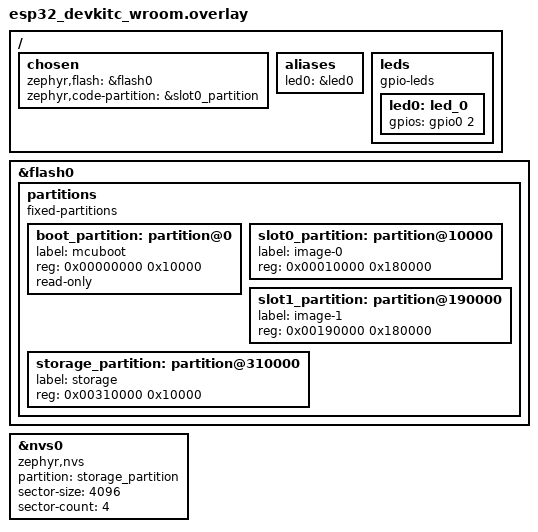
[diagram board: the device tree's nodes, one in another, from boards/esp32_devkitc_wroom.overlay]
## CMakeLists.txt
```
cmake_minimum_required(VERSION 3.20.0)

find_package(Zephyr REQUIRED HINTS $ENV{ZEPHYR_BASE})
project(esp32_wifi_ota)

target_sources(app PRIVATE
    src/main.c
    src/wifi_manager.c
    src/web_server.c
    src/ota_manager.c
    src/storage.c
)

target_include_directories(app PRIVATE
    src/
)
```

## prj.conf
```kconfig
# Networking
CONFIG_NETWORKING=y
CONFIG_NET_IPV4=y
CONFIG_NET_IPV6=n
CONFIG_NET_TCP=y
CONFIG_NET_UDP=y
CONFIG_NET_DHCPV4=y

# WiFi
CONFIG_WIFI=y
CONFIG_WIFI_ESP32=y
CONFIG_NET_L2_WIFI_MGMT=y
CONFIG_NET_L2_WIFI_SHELL=y

# HTTP Server
CONFIG_HTTP_SERVER=y
CONFIG_NET_SOCKETS=y

# Flash and Storage
CONFIG_FLASH=y
CONFIG_FLASH_MAP=y
CONFIG_NVS=y
CONFIG_SETTINGS=y
CONFIG_SETTINGS_NVS=y

# MCUboot/DFU
CONFIG_BOOTLOADER_MCUBOOT=y
CONFIG_MCUBOOT_SIGNATURE_KEY_FILE="bootloader/mcuboot/root-rsa-2048.pem"
CONFIG_IMG_MANAGER=y
CONFIG_MCUMGR=y
CONFIG_MCUMGR_GRP_IMG=y
CONFIG_MCUMGR_GRP_OS=y

# Shell
CONFIG_SHELL=y
CONFIG_DEVICE_SHELL=y

# Logging
CONFIG_LOG=y
CONFIG_LOG_DEFAULT_LEVEL=3

# System
CONFIG_MAIN_STACK_SIZE=8192
CONFIG_SYSTEM_WORKQUEUE_STACK_SIZE=2048
CONFIG_NET_TX_STACK_SIZE=2048
CONFIG_NET_RX_STACK_SIZE=2048

# Memory
CONFIG_HEAP_MEM_POOL_SIZE=131072

# JSON
CONFIG_JSON_LIBRARY=y

# Base64
CONFIG_BASE64=y
```

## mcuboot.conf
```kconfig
CONFIG_BOOT_SIGNATURE_TYPE_RSA=y
CONFIG_BOOT_SIGNATURE_KEY_FILE="bootloader/mcuboot/root-rsa-2048.pem"
CONFIG_BOOT_UPGRADE_ONLY=y
CONFIG_BOOT_BOOTSTRAP=y
```

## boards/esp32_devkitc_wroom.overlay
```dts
/ {
    chosen {
        zephyr,flash = &flash0;
        zephyr,code-partition = &slot0_partition;
    };

    aliases {
        led0 = &led0;
    };

    leds {
        compatible = "gpio-leds";
        led0: led_0 {
            gpios = <&gpio0 2 GPIO_ACTIVE_HIGH>;
        };
    };
};

&flash0 {
    partitions {
        compatible = "fixed-partitions";
        #address-cells = <1>;
        #size-cells = <1>;

        boot_partition: partition@0 {
            label = "mcuboot";
            reg = <0x00000000 0x10000>;
            read-only;
        };

        slot0_partition: partition@10000 {
            label = "image-0";
            reg = <0x00010000 0x180000>;
        };

        slot1_partition: partition@190000 {
            label = "image-1";
            reg = <0x00190000 0x180000>;
        };

        storage_partition: partition@310000 {
            label = "storage";
            reg = <0x00310000 0x10000>;
        };
    };
};

&nvs0 {
    compatible = "zephyr,nvs";
    partition = <&storage_partition>;
    sector-size = <4096>;
    sector-count = <4>;
};
```

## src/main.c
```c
#include <zephyr/kernel.h>
#include <zephyr/device.h>
#include <zephyr/logging/log.h>
#include <zephyr/net/net_if.h>
#include <zephyr/net/net_mgmt.h>
#include <zephyr/drivers/gpio.h>

#include "wifi_manager.h"
#include "web_server.h"
#include "storage.h"

LOG_MODULE_REGISTER(main);

// Check if LED is defined in devicetree, if not define a dummy
#if DT_NODE_EXISTS(DT_ALIAS(led0))
static const struct gpio_dt_spec led = GPIO_DT_SPEC_GET(DT_ALIAS(led0), gpios);
#define LED_AVAILABLE 1
#else
#define LED_AVAILABLE 0
#endif

static struct net_mgmt_event_callback wifi_cb;
static struct net_mgmt_event_callback ipv4_cb;

static void wifi_mgmt_event_handler(struct net_mgmt_event_callback *cb,
                                   uint64_t mgmt_event, struct net_if *iface)
{
    switch (mgmt_event) {
    case NET_EVENT_WIFI_CONNECT_RESULT:
        LOG_INF("WiFi connected");
#if LED_AVAILABLE
        if (device_is_ready(led.port)) {
            gpio_pin_set_dt(&led, 1);
        }
#endif
        break;
    case NET_EVENT_WIFI_DISCONNECT_RESULT:
        LOG_INF("WiFi disconnected");
#if LED_AVAILABLE
        if (device_is_ready(led.port)) {
            gpio_pin_set_dt(&led, 0);
        }
#endif
        break;
    default:
        break;
    }
}

static void ipv4_mgmt_event_handler(struct net_mgmt_event_callback *cb,
                                   uint64_t mgmt_event, struct net_if *iface)
{
    if (mgmt_event == NET_EVENT_IPV4_ADDR_ADD) {
        char buf[NET_IPV4_ADDR_LEN];
        
        LOG_INF("IPv4 address added");
        
        // Get the first IPv4 address from the interface
        struct net_if_ipv4 *ipv4 = iface->config.ip.ipv4;
        if (ipv4 && ipv4->unicast) {
            struct in_addr *addr = &ipv4->unicast[0].address.in_addr;
            if (net_addr_ntop(AF_INET, addr, buf, sizeof(buf))) {
                LOG_INF("Address: %s", buf);
                
                // Start web server once we have IP
                web_server_start();
            }
        }
    }
}

int main(void)
{
    int ret;
    
    LOG_INF("ESP32 WiFi Provisioning & OTA Update Demo");
    LOG_INF("Zephyr-based WiFi OTA system initialized");
    
    // Initialize LED if available
#if LED_AVAILABLE
    if (device_is_ready(led.port)) {
        ret = gpio_pin_configure_dt(&led, GPIO_OUTPUT_INACTIVE);
        if (ret < 0) {
            LOG_WRN("Failed to configure LED pin");
        }
    } else {
        LOG_WRN("LED device not ready");
    }
#else
    LOG_INF("No LED configured");
#endif
    
    // Initialize storage
    ret = storage_init();
    if (ret) {
        LOG_ERR("Failed to initialize storage: %d", ret);
        return ret;
    }
    
    // Set up network event callbacks
    net_mgmt_init_event_callback(&wifi_cb, wifi_mgmt_event_handler,
                                NET_EVENT_WIFI_CONNECT_RESULT |
                                NET_EVENT_WIFI_DISCONNECT_RESULT);
    net_mgmt_add_event_callback(&wifi_cb);
    
    net_mgmt_init_event_callback(&ipv4_cb, ipv4_mgmt_event_handler,
                                NET_EVENT_IPV4_ADDR_ADD);
    net_mgmt_add_event_callback(&ipv4_cb);
    
    // Initialize WiFi manager
    ret = wifi_manager_init();
    if (ret) {
        LOG_ERR("Failed to initialize WiFi manager: %d", ret);
        return ret;
    }
    
    // Try to connect with saved credentials
    wifi_manager_connect_saved();
    
    LOG_INF("System initialized. Connect to AP mode or configure WiFi.");
    
    return 0;
}
```

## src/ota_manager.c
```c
#include <zephyr/kernel.h>
#include <zephyr/storage/flash_map.h>
#include <zephyr/dfu/mcuboot.h>
#include <zephyr/logging/log.h>
#include <zephyr/net/socket.h>
#include <zephyr/net/http/client.h>
#include <string.h>

#include "ota_manager.h"

LOG_MODULE_REGISTER(ota_manager);

#define FLASH_AREA_IMAGE_SECONDARY FIXED_PARTITION_ID(slot1_partition)

static const struct flash_area *flash_area;
static size_t bytes_written = 0;
static bool update_in_progress = false;

int ota_manager_init(void)
{
    int ret = flash_area_open(FLASH_AREA_IMAGE_SECONDARY, &flash_area);
    if (ret) {
        LOG_ERR("Failed to open flash area: %d", ret);
        return ret;
    }
    
    LOG_INF("OTA manager initialized");
    return 0;
}

int ota_manager_start_update(void)
{
    if (update_in_progress) {
        LOG_WRN("Update already in progress");
        return -EBUSY;
    }
    
    if (!flash_area) {
        int ret = ota_manager_init();
        if (ret) {
            return ret;
        }
    }
    
    // Erase the secondary slot
    int ret = flash_area_erase(flash_area, 0, flash_area->fa_size);
    if (ret) {
        LOG_ERR("Failed to erase flash area: %d", ret);
        return ret;
    }
    
    bytes_written = 0;
    update_in_progress = true;
    
    LOG_INF("OTA update started");
    return 0;
}

int ota_manager_write_data(const uint8_t *data, size_t len)
{
    if (!update_in_progress) {
        LOG_ERR("No update in progress");
        return -EINVAL;
    }
    
    if (!flash_area) {
        LOG_ERR("Flash area not initialized");
        return -EINVAL;
    }
    
    if (bytes_written + len > flash_area->fa_size) {
        LOG_ERR("Data too large for flash area");
        return -ENOSPC;
    }
    
    int ret = flash_area_write(flash_area, bytes_written, data, len);
    if (ret) {
        LOG_ERR("Failed to write to flash: %d", ret);
        return ret;
    }
    
    bytes_written += len;
    
    if (bytes_written % 4096 == 0) {  // Log every 4KB
        LOG_INF("Written %zu bytes", bytes_written);
    }
    
    return 0;
}

int ota_manager_finish_update(void)
{
    if (!update_in_progress) {
        LOG_ERR("No update in progress");
        return -EINVAL;
    }
    
    update_in_progress = false;
    
    if (bytes_written == 0) {
        LOG_ERR("No data written");
        return -EINVAL;
    }
    
    // Mark the image for test (MCUboot will try it on next boot)
    int ret = boot_request_upgrade(BOOT_UPGRADE_TEST);
    if (ret) {
        LOG_ERR("Failed to request upgrade: %d", ret);
        return ret;
    }
    
    LOG_INF("OTA update finished, %zu bytes written", bytes_written);
    return 0;
}

int ota_manager_update_from_url(const char *url)
{
    // This is a simplified implementation
    // In a real implementation, you would:
    // 1. Parse the URL
    // 2. Create HTTP client
    // 3. Download the firmware
    // 4. Write it using the functions above
    
    LOG_INF("URL update not fully implemented: %s", url);
    return -ENOSYS;
}

int ota_manager_get_status(char *buf, size_t buf_len)
{
    if (!buf || buf_len == 0) {
        return -EINVAL;
    }
    
    if (update_in_progress) {
        snprintf(buf, buf_len, 
                "{\"status\":\"updating\",\"bytes_written\":%zu}", 
                bytes_written);
    } else {
        snprintf(buf, buf_len, "{\"status\":\"ready\"}");
    }
    
    return 0;
}
```

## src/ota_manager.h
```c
#ifndef OTA_MANAGER_H
#define OTA_MANAGER_H

#include <stddef.h>

int ota_manager_init(void);
int ota_manager_start_update(void);
int ota_manager_write_data(const uint8_t *data, size_t len);
int ota_manager_finish_update(void);
int ota_manager_update_from_url(const char *url);
int ota_manager_get_status(char *buf, size_t buf_len);

#endif
```

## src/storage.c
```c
#include <zephyr/kernel.h>
#include <zephyr/settings/settings.h>
#include <zephyr/logging/log.h>
#include <string.h>

#include "storage.h"

LOG_MODULE_REGISTER(storage);

#define WIFI_CREDS_KEY "wifi/creds"

int storage_init(void)
{
    int ret = settings_subsys_init();
    if (ret) {
        LOG_ERR("Failed to initialize settings: %d", ret);
        return ret;
    }
    
    LOG_INF("Storage initialized");
    return 0;
}

int storage_save_wifi_credentials(const struct wifi_credentials *creds)
{
    if (!creds) {
        return -EINVAL;
    }
    
    int ret = settings_save_one(WIFI_CREDS_KEY, creds, sizeof(*creds));
    if (ret) {
        LOG_ERR("Failed to save WiFi credentials: %d", ret);
    } else {
        LOG_INF("WiFi credentials saved");
    }
    
    return ret;
}

int storage_load_wifi_credentials(struct wifi_credentials *creds)
{
    if (!creds) {
        return -EINVAL;
    }
    
    size_t len = sizeof(*creds);
    int ret = settings_load_one(WIFI_CREDS_KEY, creds, &len);
    if (ret) {
        LOG_DBG("No saved WiFi credentials found");
        memset(creds, 0, sizeof(*creds));
        return ret;
    }
    
    if (len != sizeof(*creds) || !creds->valid) {
        LOG_WRN("Invalid WiFi credentials in storage");
        memset(creds, 0, sizeof(*creds));
        return -EINVAL;
    }
    
    LOG_INF("WiFi credentials loaded");
    return 0;
}

int storage_clear_wifi_credentials(void)
{
    int ret = settings_delete(WIFI_CREDS_KEY);
    if (ret) {
        LOG_ERR("Failed to clear WiFi credentials: %d", ret);
    } else {
        LOG_INF("WiFi credentials cleared");
    }
    
    return ret;
}
```

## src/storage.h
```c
#ifndef STORAGE_H
#define STORAGE_H

#include "wifi_manager.h"

int storage_init(void);
int storage_save_wifi_credentials(const struct wifi_credentials *creds);
int storage_load_wifi_credentials(struct wifi_credentials *creds);
int storage_clear_wifi_credentials(void);

#endif
```

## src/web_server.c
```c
#include <zephyr/kernel.h>
#include <zephyr/net/socket.h>
#include <zephyr/net/http/service.h>
#include <zephyr/logging/log.h>
#include <zephyr/fs/fs.h>
#include <zephyr/sys/reboot.h>
#include <string.h>
#include <stdio.h>

#include "web_server.h"
#include "wifi_manager.h"
#include "ota_manager.h"

LOG_MODULE_REGISTER(web_server);

#define HTTP_PORT 80

// Simple HTML content
static const char index_html[] = 
"<!DOCTYPE html>\n"
"<html>\n"
"<head>\n"
"    <title>ESP32 WiFi & OTA Manager</title>\n"
"    <meta name=\"viewport\" content=\"width=device-width, initial-scale=1\">\n"
"    <style>\n"
"        body { font-family: Arial, sans-serif; margin: 20px; }\n"
"        .section { margin: 20px 0; padding: 20px; border: 1px solid #ddd; }\n"
"        input, button { padding: 10px; margin: 5px; }\n"
"        button { background: #4CAF50; color: white; border: none; cursor: pointer; }\n"
"    </style>\n"
"</head>\n"
"<body>\n"
"    <h1>ESP32 WiFi & OTA Manager</h1>\n"
"    <div class=\"section\">\n"
"        <h2>WiFi Configuration</h2>\n"
"        <div id=\"wifi-status\">Loading...</div>\n"
"        <form id=\"wifi-form\">\n"
"            <input type=\"text\" id=\"ssid\" placeholder=\"WiFi SSID\" required>\n"
"            <input type=\"password\" id=\"password\" placeholder=\"WiFi Password\">\n"
"            <button type=\"submit\">Connect</button>\n"
"        </form>\n"
"    </div>\n"
"    <div class=\"section\">\n"
"        <h2>System Info</h2>\n"
"        <div id=\"system-info\">Loading...</div>\n"
"        <button onclick=\"rebootDevice()\">Reboot</button>\n"
"    </div>\n"
"    <script>\n"
"        function loadSystemInfo() {\n"
"            fetch('/api/system/info')\n"
"                .then(response => response.json())\n"
"                .then(data => {\n"
"                    document.getElementById('system-info').innerHTML = \n"
"                        'Version: ' + data.version + '<br>' +\n"
"                        'Free Memory: ' + data.free_memory + ' bytes<br>' +\n"
"                        'Uptime: ' + data.uptime + ' seconds';\n"
"                });\n"
"        }\n"
"        function rebootDevice() {\n"
"            if (confirm('Reboot?')) {\n"
"                fetch('/api/system/reboot', { method: 'POST' });\n"
"            }\n"
"        }\n"
"        loadSystemInfo();\n"
"    </script>\n"
"</body>\n"
"</html>";

// Handler for index page
static int index_handler(struct http_client_ctx *client, enum http_data_status status,
                        const struct http_request_ctx *request_ctx,
                        struct http_response_ctx *response_ctx, void *user_data)
{
    if (status == HTTP_SERVER_DATA_FINAL) {
        response_ctx->status = 200;
        response_ctx->headers = (struct http_header[]){
            {"Content-Type", "text/html"}
        };
        response_ctx->header_count = 1;
        response_ctx->body = index_html;
        response_ctx->body_len = strlen(index_html);
        response_ctx->final_chunk = true;
    }
    return 0;
}

// Handler for system info API
static int api_system_info_handler(struct http_client_ctx *client, enum http_data_status status,
                                   const struct http_request_ctx *request_ctx,
                                   struct http_response_ctx *response_ctx, void *user_data)
{
    if (status == HTTP_SERVER_DATA_FINAL) {
        static char response_buf[512];
        uint32_t uptime = k_uptime_get() / 1000;
        
        snprintf(response_buf, sizeof(response_buf),
                 "{"
                 "\"version\":\"1.0.0\","
                 "\"build_date\":\"%s %s\","
                 "\"free_memory\":%zu,"
                 "\"uptime\":%u"
                 "}",
                 __DATE__, __TIME__,
                 k_mem_free_get(),
                 uptime);
        
        response_ctx->status = 200;
        response_ctx->headers = (struct http_header[]){
            {"Content-Type", "application/json"}
        };
        response_ctx->header_count = 1;
        response_ctx->body = response_buf;
        response_ctx->body_len = strlen(response_buf);
        response_ctx->final_chunk = true;
    }
    return 0;
}

// Handler for system reboot API
static int api_system_reboot_handler(struct http_client_ctx *client, enum http_data_status status,
                                     const struct http_request_ctx *request_ctx,
                                     struct http_response_ctx *response_ctx, void *user_data)
{
    if (status == HTTP_SERVER_DATA_FINAL) {
        const char *response = "{\"success\":true,\"message\":\"Rebooting...\"}";
        
        response_ctx->status = 200;
        response_ctx->headers = (struct http_header[]){
            {"Content-Type", "application/json"}
        };
        response_ctx->header_count = 1;
        response_ctx->body = response;
        response_ctx->body_len = strlen(response);
        response_ctx->final_chunk = true;
        
        // Reboot after a short delay
        k_sleep(K_MSEC(1000));
        sys_reboot(SYS_REBOOT_WARM);
    }
    return 0;
}

// Handler for WiFi status API
static int api_wifi_status_handler(struct http_client_ctx *client, enum http_data_status status,
                                   const struct http_request_ctx *request_ctx,
                                   struct http_response_ctx *response_ctx, void *user_data)
{
    if (status == HTTP_SERVER_DATA_FINAL) {
        static char response_buf[256];
        
        wifi_manager_get_status(response_buf, sizeof(response_buf));
        
        response_ctx->status = 200;
        response_ctx->headers = (struct http_header[]){
            {"Content-Type", "application/json"}
        };
        response_ctx->header_count = 1;
        response_ctx->body = response_buf;
        response_ctx->body_len = strlen(response_buf);
        response_ctx->final_chunk = true;
    }
    return 0;
}

// Handler for WiFi connect API
static int api_wifi_connect_handler(struct http_client_ctx *client, enum http_data_status status,
                                    const struct http_request_ctx *request_ctx,
                                    struct http_response_ctx *response_ctx, void *user_data)
{
    static char request_buffer[512];
    static size_t total_received = 0;
    
    if (status == HTTP_SERVER_DATA_MORE) {
        // Accumulate POST data
        if (total_received + request_ctx->data_len < sizeof(request_buffer)) {
            memcpy(request_buffer + total_received, request_ctx->data, request_ctx->data_len);
            total_received += request_ctx->data_len;
        }
        return 0;
    }
    
    if (status == HTTP_SERVER_DATA_FINAL) {
        // Complete request received
        if (total_received + request_ctx->data_len < sizeof(request_buffer)) {
            memcpy(request_buffer + total_received, request_ctx->data, request_ctx->data_len);
            total_received += request_ctx->data_len;
            request_buffer[total_received] = '\0';
        }
        
        // Process WiFi connection request (simple JSON parsing)
        static char response_buf[256];
        char ssid[64] = {0};
        char password[64] = {0};
        
        // Simple JSON parsing for SSID and password
        char *ssid_start = strstr(request_buffer, "\"ssid\":\"");
        char *password_start = strstr(request_buffer, "\"password\":\"");
        
        if (ssid_start) {
            ssid_start += 8; // Move past "ssid":"
            char *ssid_end = strchr(ssid_start, '"');
            if (ssid_end && (ssid_end - ssid_start) < sizeof(ssid) - 1) {
                strncpy(ssid, ssid_start, ssid_end - ssid_start);
            }
        }
        
        if (password_start) {
            password_start += 12; // Move past "password":"
            char *password_end = strchr(password_start, '"');
            if (password_end && (password_end - password_start) < sizeof(password) - 1) {
                strncpy(password, password_start, password_end - password_start);
            }
        }
        
        int ret = wifi_manager_connect(ssid, password);
        
        if (ret == 0) {
            snprintf(response_buf, sizeof(response_buf),
                     "{\"success\":true,\"message\":\"Connecting to WiFi...\"}");
        } else {
            snprintf(response_buf, sizeof(response_buf),
                     "{\"success\":false,\"message\":\"Failed to connect\"}");
        }
        
        response_ctx->status = 200;
        response_ctx->headers = (struct http_header[]){
            {"Content-Type", "application/json"}
        };
        response_ctx->header_count = 1;
        response_ctx->body = response_buf;
        response_ctx->body_len = strlen(response_buf);
        response_ctx->final_chunk = true;
        
        total_received = 0; // Reset for next request
    }
    
    return 0;
}

// Handler for WiFi scan API
static int api_wifi_scan_handler(struct http_client_ctx *client, enum http_data_status status,
                                 const struct http_request_ctx *request_ctx,
                                 struct http_response_ctx *response_ctx, void *user_data)
{
    if (status == HTTP_SERVER_DATA_FINAL) {
        static char response_buf[1024];
        
        // Trigger WiFi scan and return simple response
        int ret = wifi_manager_scan();
        if (ret == 0) {
            snprintf(response_buf, sizeof(response_buf),
                     "{\"success\":true,\"message\":\"WiFi scan started\"}");
        } else {
            snprintf(response_buf, sizeof(response_buf),
                     "{\"success\":false,\"message\":\"Failed to start scan\"}");
        }
        
        response_ctx->status = 200;
        response_ctx->headers = (struct http_header[]){
            {"Content-Type", "application/json"}
        };
        response_ctx->header_count = 1;
        response_ctx->body = response_buf;
        response_ctx->body_len = strlen(response_buf);
        response_ctx->final_chunk = true;
    }
    return 0;
}

// Resource definitions
static struct http_resource_detail_dynamic index_resource_detail = {
    .common = {
        .type = HTTP_RESOURCE_TYPE_DYNAMIC,
        .bitmask_of_supported_http_methods = BIT(HTTP_GET),
    },
    .cb = index_handler,
    .user_data = NULL,
};

static struct http_resource_detail_dynamic api_system_info_resource_detail = {
    .common = {
        .type = HTTP_RESOURCE_TYPE_DYNAMIC,
        .bitmask_of_supported_http_methods = BIT(HTTP_GET),
    },
    .cb = api_system_info_handler,
    .user_data = NULL,
};

static struct http_resource_detail_dynamic api_system_reboot_resource_detail = {
    .common = {
        .type = HTTP_RESOURCE_TYPE_DYNAMIC,
        .bitmask_of_supported_http_methods = BIT(HTTP_POST),
    },
    .cb = api_system_reboot_handler,
    .user_data = NULL,
};

static struct http_resource_detail_dynamic api_wifi_status_resource_detail = {
    .common = {
        .type = HTTP_RESOURCE_TYPE_DYNAMIC,
        .bitmask_of_supported_http_methods = BIT(HTTP_GET),
    },
    .cb = api_wifi_status_handler,
    .user_data = NULL,
};

static struct http_resource_detail_dynamic api_wifi_connect_resource_detail = {
    .common = {
        .type = HTTP_RESOURCE_TYPE_DYNAMIC,
        .bitmask_of_supported_http_methods = BIT(HTTP_POST),
    },
    .cb = api_wifi_connect_handler,
    .user_data = NULL,
};

static struct http_resource_detail_dynamic api_wifi_scan_resource_detail = {
    .common = {
        .type = HTTP_RESOURCE_TYPE_DYNAMIC,
        .bitmask_of_supported_http_methods = BIT(HTTP_GET),
    },
    .cb = api_wifi_scan_handler,
    .user_data = NULL,
};

// HTTP resources - defined in a special section
HTTP_RESOURCE_DEFINE(index_resource, my_service, "/", &index_resource_detail);
HTTP_RESOURCE_DEFINE(api_system_info_resource, my_service, "/api/system/info", &api_system_info_resource_detail);
HTTP_RESOURCE_DEFINE(api_system_reboot_resource, my_service, "/api/system/reboot", &api_system_reboot_resource_detail);
HTTP_RESOURCE_DEFINE(api_wifi_status_resource, my_service, "/api/wifi/status", &api_wifi_status_resource_detail);
HTTP_RESOURCE_DEFINE(api_wifi_connect_resource, my_service, "/api/wifi/connect", &api_wifi_connect_resource_detail);
HTTP_RESOURCE_DEFINE(api_wifi_scan_resource, my_service, "/api/wifi/scan", &api_wifi_scan_resource_detail);

// HTTP service
static uint16_t http_service_port = HTTP_PORT;
HTTP_SERVICE_DEFINE(my_service, "0.0.0.0", &http_service_port, 1, 10, NULL);

int web_server_start(void)
{
    // In Zephyr 4.2.0, HTTP services start automatically when defined
    // No explicit start function is needed
    LOG_INF("HTTP server configured on port %d", HTTP_PORT);
    return 0;
}

int web_server_stop(void)
{
    // In Zephyr 4.2.0, HTTP services cannot be stopped dynamically
    // They are controlled by the system
    LOG_INF("HTTP server stop requested (not supported in Zephyr 4.2.0)");
    return 0;
}
```

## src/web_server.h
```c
#ifndef WEB_SERVER_H
#define WEB_SERVER_H

int web_server_start(void);
int web_server_stop(void);

#endif
```

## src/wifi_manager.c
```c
#include <zephyr/kernel.h>
#include <zephyr/net/net_if.h>
#include <zephyr/net/wifi_mgmt.h>
#include <zephyr/logging/log.h>
#include <string.h>

#include "wifi_manager.h"
#include "storage.h"

LOG_MODULE_REGISTER(wifi_manager);

static struct net_if *wifi_iface;
static bool connected = false;
static bool ap_mode = false;

int wifi_manager_init(void)
{
    wifi_iface = net_if_get_default();
    if (!wifi_iface) {
        LOG_ERR("No default network interface");
        return -ENODEV;
    }
    
    LOG_INF("WiFi manager initialized");
    return 0;
}

int wifi_manager_scan(void)
{
    if (!wifi_iface) {
        return -ENODEV;
    }
    
    return net_mgmt(NET_REQUEST_WIFI_SCAN, wifi_iface, NULL, 0);
}

int wifi_manager_connect(const char *ssid, const char *psk)
{
    struct wifi_connect_req_params params = {0};
    
    if (!wifi_iface || !ssid) {
        return -EINVAL;
    }
    
    params.ssid = (uint8_t *)ssid;
    params.ssid_length = strlen(ssid);
    params.security = WIFI_SECURITY_TYPE_PSK;
    
    if (psk && strlen(psk) > 0) {
        params.psk = (uint8_t *)psk;
        params.psk_length = strlen(psk);
    } else {
        params.security = WIFI_SECURITY_TYPE_NONE;
    }
    
    params.channel = WIFI_CHANNEL_ANY;
    params.band = WIFI_FREQ_BAND_2_4_GHZ;
    params.mfp = WIFI_MFP_OPTIONAL;
    
    LOG_INF("Connecting to WiFi SSID: %s", ssid);
    
    int ret = net_mgmt(NET_REQUEST_WIFI_CONNECT, wifi_iface, &params, sizeof(params));
    if (ret == 0) {
        // Save credentials
        struct wifi_credentials creds = {0};
        strncpy(creds.ssid, ssid, sizeof(creds.ssid) - 1);
        if (psk) {
            strncpy(creds.psk, psk, sizeof(creds.psk) - 1);
        }
        creds.valid = true;
        storage_save_wifi_credentials(&creds);
    }
    
    return ret;
}

int wifi_manager_connect_saved(void)
{
    struct wifi_credentials creds;
    
    if (storage_load_wifi_credentials(&creds) == 0 && creds.valid) {
        LOG_INF("Connecting with saved credentials");
        return wifi_manager_connect(creds.ssid, creds.psk);
    }
    
    LOG_INF("No saved credentials, starting AP mode");
    return wifi_manager_start_ap();
}

int wifi_manager_disconnect(void)
{
    if (!wifi_iface) {
        return -ENODEV;
    }
    
    connected = false;
    return net_mgmt(NET_REQUEST_WIFI_DISCONNECT, wifi_iface, NULL, 0);
}

int wifi_manager_start_ap(void)
{
    struct wifi_connect_req_params params = {0};
    const char *ap_ssid = "ESP32-Config";
    const char *ap_psk = "12345678";
    
    if (!wifi_iface) {
        return -ENODEV;
    }
    
    params.ssid = (uint8_t *)ap_ssid;
    params.ssid_length = strlen(ap_ssid);
    params.psk = (uint8_t *)ap_psk;
    params.psk_length = strlen(ap_psk);
    params.security = WIFI_SECURITY_TYPE_PSK;
    params.channel = 6;
    params.band = WIFI_FREQ_BAND_2_4_GHZ;
    
    LOG_INF("Starting AP mode: %s", ap_ssid);
    
    int ret = net_mgmt(NET_REQUEST_WIFI_AP_ENABLE, wifi_iface, &params, sizeof(params));
    if (ret == 0) {
        ap_mode = true;
    }
    
    return ret;
}

int wifi_manager_stop_ap(void)
{
    if (!wifi_iface) {
        return -ENODEV;
    }
    
    ap_mode = false;
    return net_mgmt(NET_REQUEST_WIFI_AP_DISABLE, wifi_iface, NULL, 0);
}

bool wifi_manager_is_connected(void)
{
    return connected && !ap_mode;
}

int wifi_manager_get_status(char *buf, size_t buf_len)
{
    if (!buf || buf_len == 0) {
        return -EINVAL;
    }
    
    if (ap_mode) {
        snprintf(buf, buf_len, "{\"status\":\"ap_mode\",\"ssid\":\"ESP32-Config\"}");
    } else if (connected) {
        snprintf(buf, buf_len, "{\"status\":\"connected\"}");
    } else {
        snprintf(buf, buf_len, "{\"status\":\"disconnected\"}");
    }
    
    return 0;
}
```

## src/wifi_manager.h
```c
#ifndef WIFI_MANAGER_H
#define WIFI_MANAGER_H

#include <zephyr/net/wifi_mgmt.h>

#define WIFI_SSID_MAX_LEN 32
#define WIFI_PSK_MAX_LEN 64

struct wifi_credentials {
    char ssid[WIFI_SSID_MAX_LEN + 1];
    char psk[WIFI_PSK_MAX_LEN + 1];
    bool valid;
};

int wifi_manager_init(void);
int wifi_manager_scan(void);
int wifi_manager_connect(const char *ssid, const char *psk);
int wifi_manager_connect_saved(void);
int wifi_manager_disconnect(void);
int wifi_manager_start_ap(void);
int wifi_manager_stop_ap(void);
bool wifi_manager_is_connected(void);
int wifi_manager_get_status(char *buf, size_t buf_len);

#endif
```
